# STM32G431C6T6 register map
File version: 1.0
Registers are 32-bit, access not given, reset 0x0 unless marked. A register's access mark holds for its fields unless they carry their own. Offsets are from the block's base; [hi:lo] are bit positions; {n}, {i} and the like mark numbered series; 'fields as' and 'values as' point back to an identical list.

## LPUART1
Base 0x40008000
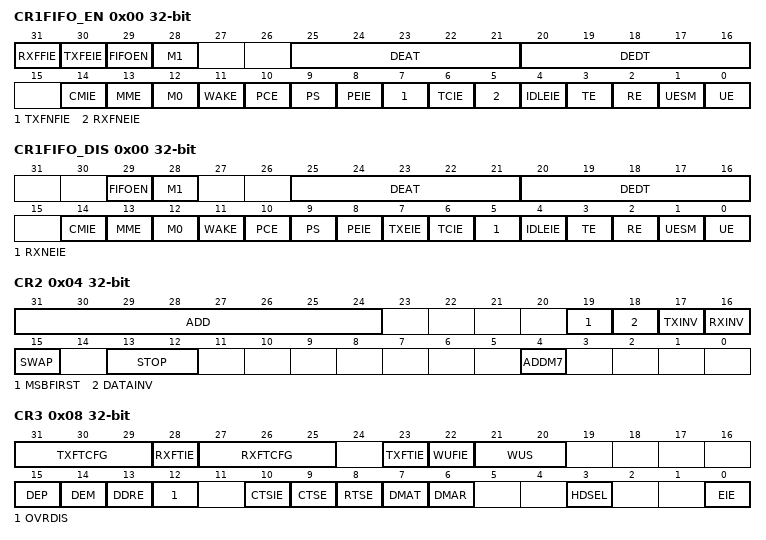
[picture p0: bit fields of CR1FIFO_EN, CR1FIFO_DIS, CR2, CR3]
0x00 CR1FIFO_EN
  [31] RXFFIE, [30] TXFEIE, [29] FIFOEN, [28] M1, [25:21] DEAT, [20:16] DEDT, [14] CMIE, [13] MME, [12] M0, [11] WAKE, [10] PCE, [9] PS, [8] PEIE, [7] TXFNFIE, [6] TCIE, [5] RXFNEIE, [4] IDLEIE, [3] TE, [2] RE, [1] UESM, [0] UE
0x00 CR1FIFO_DIS
  [29] FIFOEN, [28] M1, [25:21] DEAT, [20:16] DEDT, [14] CMIE, [13] MME, [12] M0, [11] WAKE, [10] PCE, [9] PS, [8] PEIE, [7] TXEIE, [6] TCIE, [5] RXNEIE, [4] IDLEIE, [3] TE, [2] RE, [1] UESM, [0] UE
0x04 CR2
  [31:24] ADD, [19] MSBFIRST, [18] DATAINV, [17] TXINV, [16] RXINV, [15] SWAP, [13:12] STOP, [4] ADDM7
0x08 CR3
  [31:29] TXFTCFG, [28] RXFTIE, [27:25] RXFTCFG, [23] TXFTIE, [22] WUFIE, [21:20] WUS, [15] DEP, [14] DEM, [13] DDRE, [12] OVRDIS, [10] CTSIE, [9] CTSE, [8] RTSE, [7] DMAT, [6] DMAR, [3] HDSEL, [0] EIE
0x0C BRR
  [19:0] BRR
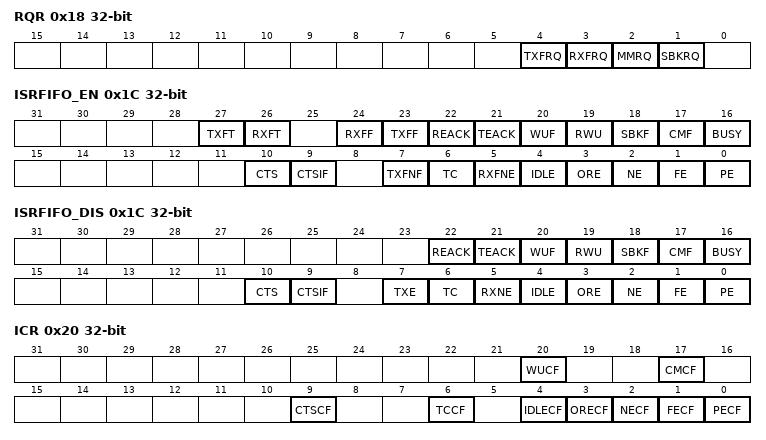
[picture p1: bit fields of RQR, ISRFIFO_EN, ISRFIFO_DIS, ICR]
0x18 RQR
  [4] TXFRQ, [3] RXFRQ, [2] MMRQ, [1] SBKRQ
0x1C ISRFIFO_EN
  [27] TXFT, [26] RXFT, [24] RXFF, [23] TXFF, [22] REACK, [21] TEACK, [20] WUF, [19] RWU, [18] SBKF, [17] CMF, [16] BUSY, [10] CTS, [9] CTSIF, [7] TXFNF, [6] TC, [5] RXFNE, [4] IDLE, [3] ORE, [2] NE, [1] FE, [0] PE
0x1C ISRFIFO_DIS
  [22] REACK, [21] TEACK, [20] WUF, [19] RWU, [18] SBKF, [17] CMF, [16] BUSY, [10] CTS, [9] CTSIF, [7] TXE, [6] TC, [5] RXNE, [4] IDLE, [3] ORE, [2] NE, [1] FE, [0] PE
0x20 ICR
  [20] WUCF, [17] CMCF, [9] CTSCF, [6] TCCF, [4] IDLECF, [3] ORECF, [2] NECF, [1] FECF, [0] PECF
0x24 RDR
  [8:0] RDR
0x28 TDR
  [8:0] TDR
0x2C PRESC
  [3:0] PRESCALER

## UCPD1
Base 0x4000A000
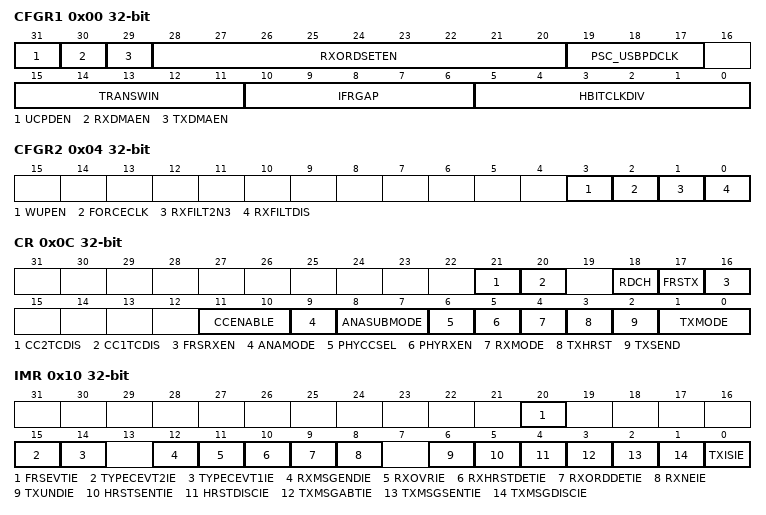
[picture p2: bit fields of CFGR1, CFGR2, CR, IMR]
0x00 CFGR1
  [31] UCPDEN, [30] RXDMAEN, [29] TXDMAEN, [28:20] RXORDSETEN, [19:17] PSC_USBPDCLK, [15:11] TRANSWIN, [10:6] IFRGAP, [5:0] HBITCLKDIV
0x04 CFGR2
  [3] WUPEN, [2] FORCECLK, [1] RXFILT2N3, [0] RXFILTDIS
0x0C CR
  [21] CC2TCDIS, [20] CC1TCDIS, [18] RDCH, [17] FRSTX, [16] FRSRXEN, [11:10] CCENABLE, [9] ANAMODE, [8:7] ANASUBMODE, [6] PHYCCSEL, [5] PHYRXEN, [4] RXMODE, [3] TXHRST, [2] TXSEND, [1:0] TXMODE
0x10 IMR
  [20] FRSEVTIE, [15] TYPECEVT2IE, [14] TYPECEVT1IE, [12] RXMSGENDIE, [11] RXOVRIE, [10] RXHRSTDETIE, [9] RXORDDETIE, [8] RXNEIE, [6] TXUNDIE, [5] HRSTSENTIE, [4] HRSTDISCIE, [3] TXMSGABTIE, [2] TXMSGSENTIE, [1] TXMSGDISCIE, [0] TXISIE
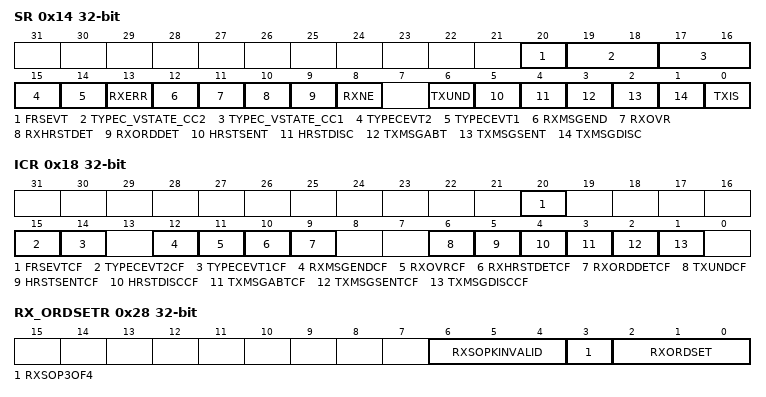
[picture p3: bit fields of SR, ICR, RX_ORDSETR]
0x14 SR
  [20] FRSEVT, [19:18] TYPEC_VSTATE_CC2, [17:16] TYPEC_VSTATE_CC1, [15] TYPECEVT2, [14] TYPECEVT1, [13] RXERR, [12] RXMSGEND, [11] RXOVR, [10] RXHRSTDET, [9] RXORDDET, [8] RXNE, [6] TXUND, [5] HRSTSENT, [4] HRSTDISC, [3] TXMSGABT, [2] TXMSGSENT, [1] TXMSGDISC, [0] TXIS
0x18 ICR
  [20] FRSEVTCF, [15] TYPECEVT2CF, [14] TYPECEVT1CF, [12] RXMSGENDCF, [11] RXOVRCF, [10] RXHRSTDETCF, [9] RXORDDETCF, [6] TXUNDCF, [5] HRSTSENTCF, [4] HRSTDISCCF, [3] TXMSGABTCF, [2] TXMSGSENTCF, [1] TXMSGDISCCF
0x1C TX_ORDSETR
  [19:0] TXORDSET
0x20 TX_PAYSZR
  [9:0] TXPAYSZ
0x24 TXDR
  [7:0] TXDATA
0x28 RX_ORDSETR
  [6:4] RXSOPKINVALID, [3] RXSOP3OF4, [2:0] RXORDSET
0x2C RX_PAYSZR
  [9:0] RXPAYSZ
0x30 RXDR
  [7:0] RXDATA
0x34 RX_ORDEXTR1
  [19:0] RXSOPX1
0x38 RX_ORDEXTR2
  [19:0] RXSOPX2

## SYSCFG
Base 0x40010000
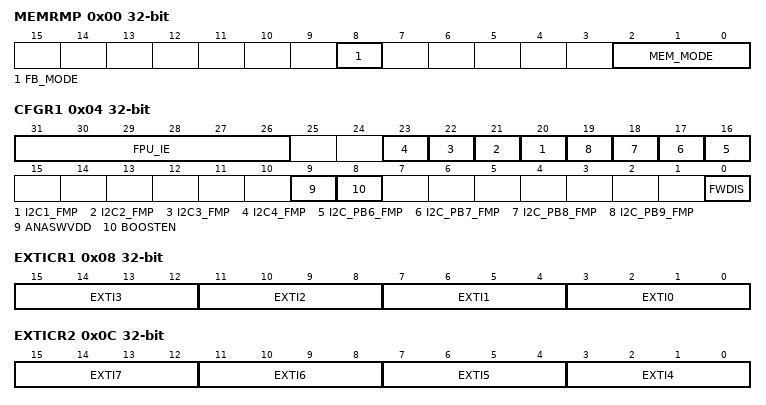
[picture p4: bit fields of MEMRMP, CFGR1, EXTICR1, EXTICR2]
0x00 MEMRMP
  [8] FB_MODE, [2:0] MEM_MODE
0x04 CFGR1
  [31:26] FPU_IE, [n+19] I2C{n}_FMP (n=1..4), [n+10] I2C_PB{n}_FMP (n=6..9), [9] ANASWVDD, [8] BOOSTEN, [0] FWDIS
0x08 EXTICR1
  [4n+3:4n] EXTI{n} (n=0..3)
0x0C EXTICR2
  [4n-13:4n-16] EXTI{n} (n=4..7)
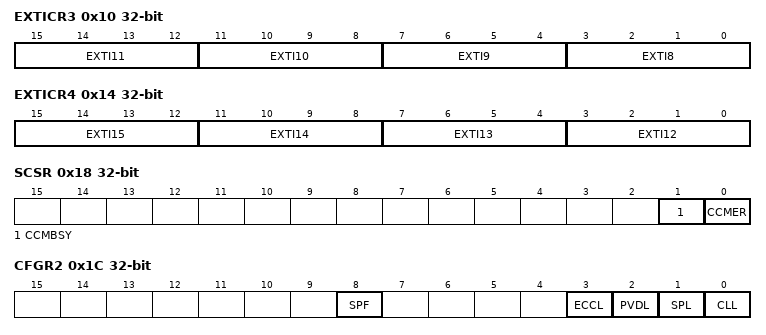
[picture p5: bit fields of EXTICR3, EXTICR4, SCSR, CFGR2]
0x10 EXTICR3
  [4n-29:4n-32] EXTI{n} (n=8..11)
0x14 EXTICR4
  [4n-45:4n-48] EXTI{n} (n=12..15)
0x18 SCSR
  [1] CCMBSY, [0] CCMER
0x1C CFGR2
  [8] SPF, [3] ECCL, [2] PVDL, [1] SPL, [0] CLL
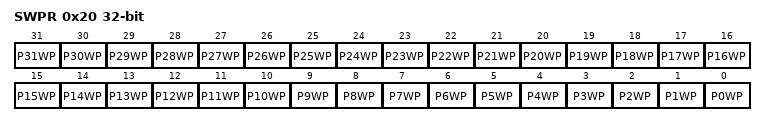
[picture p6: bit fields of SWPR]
0x20 SWPR
  [n] P{n}WP (n=0..31)
0x24 SKR
  [7:0] KEY

## VREFBUF
Base 0x40010030
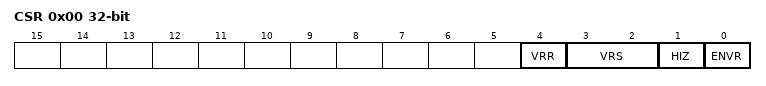
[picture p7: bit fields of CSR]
0x00 CSR
  [4] VRR, [3:2] VRS, [1] HIZ, [0] ENVR
0x04 CCR
  [5:0] TRIM

## COMP
Base 0x40010200
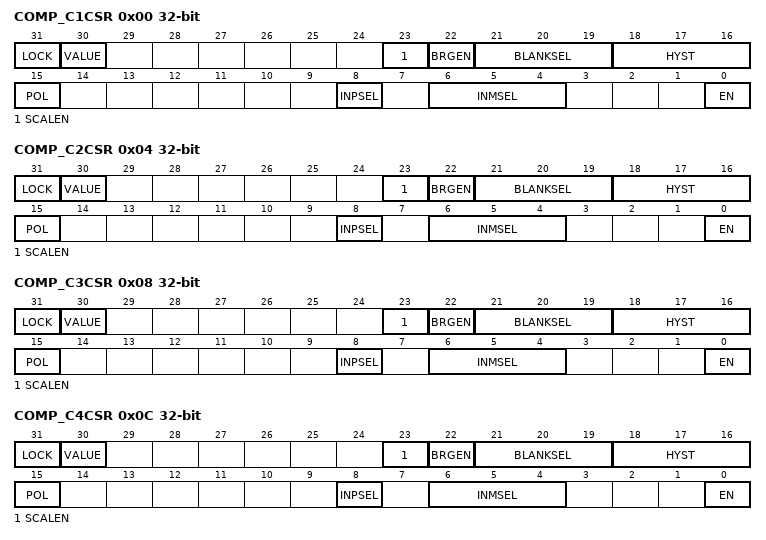
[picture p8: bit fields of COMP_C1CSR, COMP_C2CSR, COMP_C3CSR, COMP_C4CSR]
0x00 COMP_C1CSR
  [31] LOCK, [30] VALUE, [23] SCALEN, [22] BRGEN, [21:19] BLANKSEL, [18:16] HYST, [15] POL, [8] INPSEL, [6:4] INMSEL, [0] EN
0x04 COMP_C2CSR
  fields as COMP_C1CSR
0x08 COMP_C3CSR
  fields as COMP_C1CSR
0x0C COMP_C4CSR
  fields as COMP_C1CSR
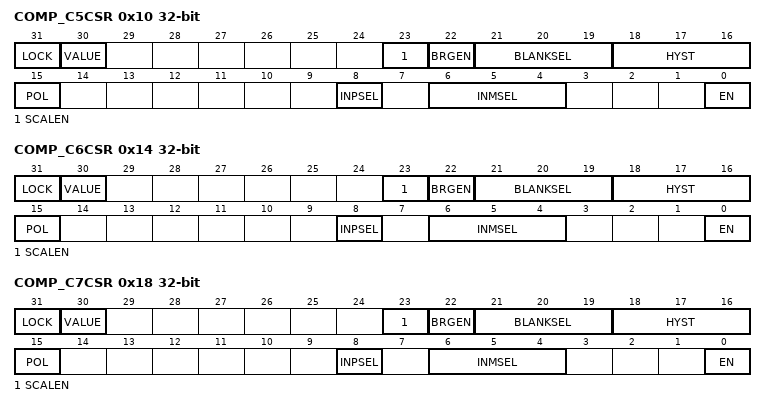
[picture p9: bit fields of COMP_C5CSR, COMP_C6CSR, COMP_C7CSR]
0x10 COMP_C5CSR
  fields as COMP_C1CSR
0x14 COMP_C6CSR
  fields as COMP_C1CSR
0x18 COMP_C7CSR
  fields as COMP_C1CSR
